# COMPUTE_CLUSTER0_DRU register map
Vendor: Texas Instruments
Peripheral module from a debugger description file (folder am65x).
Registers are 64-bit, read-only, reset 0x0 unless marked. A register's access mark holds for its fields unless they carry their own. Offsets are as the file gives them; lines under a group give offsets from that group; [hi:lo] are bit positions; {n}, {i} and the like mark numbered series; 'fields as' and 'values as' point back to an identical list; <NAME> marks a mode.

## COMPUTE_CLUSTER0_DRU
0x00 DRU_PID reset 0x662C0900 — Peripheral ID Register
  [31:0] REVISION
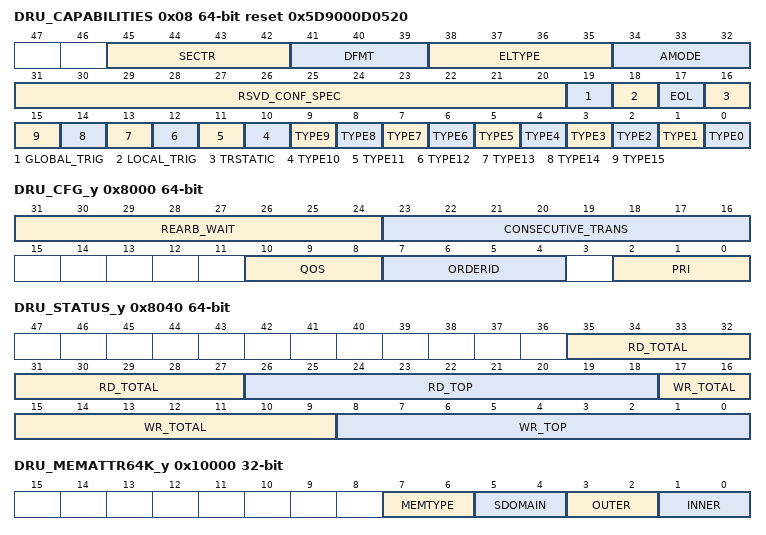
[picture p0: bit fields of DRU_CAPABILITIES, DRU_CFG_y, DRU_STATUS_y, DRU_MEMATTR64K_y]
0x08 DRU_CAPABILITIES reset 0x5D9000D0520 — DRU Capabilities: Lists the capabilities of the channel for TR TYPE and formatting functions
  [45:42] SECTR, [41:39] DFMT, [38:35] ELTYPE, [34:32] AMODE, [31:20] RSVD_CONF_SPEC, [19] GLOBAL_TRIG, [18] LOCAL_TRIG, [17] EOL, [16] TRSTATIC, [n] TYPE{n} (n=0..15)
0x4000 DRU_SHARED_EVT_SET access per field — DRU Shared Event Set Register
  [0] PROT_ERR wo
0x4040 DRU_COMP_EVT_SET0 wo — DRU Completion Event Set Register
  [n] COMP_EVT{n} (n=0..63)
0x4080 DRU_ERR_EVT_SET0 wo — DRU Error Event Set Register
  [n] ERR_EVT{n} (n=0..63)
0x40C0 DRU_LOCAL_EVT_SET0 wo — DRU Local Event Set Register
  [n] COMP_EVT{n} (n=0..63)
0x8000 DRU_CFG_y access per field — Configuration Register for Queue 'y' Offset = 8000h + (y * 8h); where y = 0h to 4h
  [31:24] REARB_WAIT rw, [23:16] CONSECUTIVE_TRANS rw, [10:8] QOS rw, [7:4] ORDERID rw, [2:0] PRI rw
0x8040 DRU_STATUS_y — Status Register for Queue 'y' Offset = 8040h + (y * 8h); where y = 0h to 4h
  [35:27] RD_TOTAL, [26:18] RD_TOP, [17:9] WR_TOTAL, [8:0] WR_TOP
0x10000 DRU_MEMATTR64K_y 32-bit rw — The Memory Attribute register contains the attributes for all the 64K mapped regions. Offset = 10000h + (y * 4h); where y = 0h to 7Fh
  [7:6] MEMTYPE — Defines the type of the memory
  [5:4] SDOMAIN — Defines the shareability domain of the memory
  [3:2] OUTER — Defines the outer allocatability of the memory
  [1:0] INNER — Defines the inner allocatability of the memory
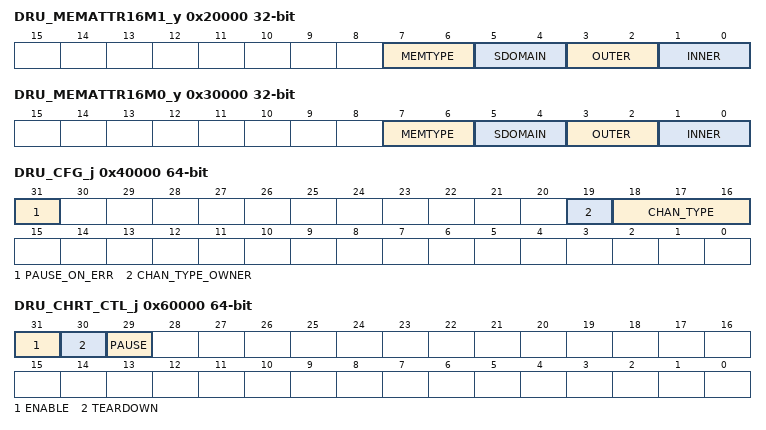
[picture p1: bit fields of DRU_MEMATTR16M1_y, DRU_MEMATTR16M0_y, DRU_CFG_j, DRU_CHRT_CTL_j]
0x20000 DRU_MEMATTR16M1_y 32-bit rw — The Memory Attribute register contains the attributes for all the second 16M mapped regions. Offset = 20000h + (y * 4h); where y = 0h to 7FFh
  fields as DRU_MEMATTR64K_y
0x30000 DRU_MEMATTR16M0_y 32-bit rw — The Memory Attribute register contains the attributes for all the first 16M mapped regions. Offset = 30000h + (y * 4h); where y = 0h to 7Fh
  fields as DRU_MEMATTR64K_y
0x40000 DRU_CFG_j access per field — Channel Configuration Register. The Channel Configuration Register is used to initialize static mode settings for the DMA Channel. The register may only be written when the chanel is disable in the ch_enable field in the REALTIME CONTROL register is 0. Offset = 40000h + (j * 100h); where j = 0h to 3Fh
  [31] PAUSE_ON_ERR rw, [19] CHAN_TYPE_OWNER rw, [18:16] CHAN_TYPE ro
0x40020 DRU_CHOES0_j access per field — The Output Event Steering Registers are used to specify a global event number to generate anytime the required event generation criteria specified in a TR are met. A single event with the event number set equal to the value in the corresponding register will be generated. This register is provided in order to allow security SW to lock down which events in the global space any given channel/ thread is allowed to generate Offset = 40020h + (j * 100h); where j = 0h to 3Fh
  [15:0] EVT_NUM rw
0x40060 DRU_CHST_SCHED_j rw — Channel Static Scheduler Config Register Offset = 40060h + (j * 100h); where j = 0h to 3Fh
  [2:0] QUEUE
0x60000 DRU_CHRT_CTL_j access per field — The channel realtime control register contains real-time cotrol and status information for the DMA Channel. The fields in this regsiter can be changed while the channel is in operation. Offset = 60000h + (j * 100h); where j = 0h to 3Fh
  [31] ENABLE rw, [30] TEARDOWN rw, [29] PAUSE rw
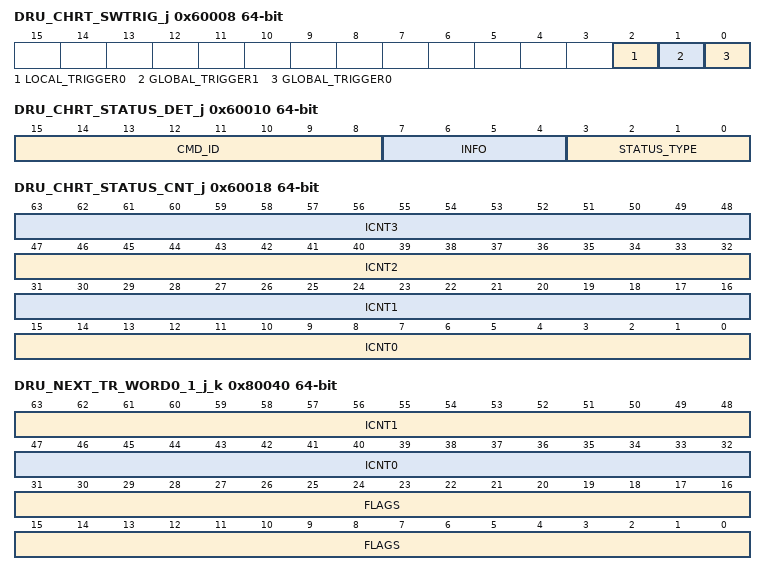
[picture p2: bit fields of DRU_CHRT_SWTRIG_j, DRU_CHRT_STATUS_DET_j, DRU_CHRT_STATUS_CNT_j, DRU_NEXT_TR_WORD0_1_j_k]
0x60008 DRU_CHRT_SWTRIG_j access per field — The Software Trigger Register provides a mechanism by which software can directly trigger the channel in a secure way. Offset = 60008h + (j * 100h); where j = 0h to 3Fh
  [2] LOCAL_TRIGGER0 rw, [1] GLOBAL_TRIGGER1 rw, [0] GLOBAL_TRIGGER0 rw
0x60010 DRU_CHRT_STATUS_DET_j — The channel status details Offset = 60010h + (j * 100h); where j = 0h to 3Fh
  [15:8] CMD_ID, [7:4] INFO, [3:0] STATUS_TYPE
0x60018 DRU_CHRT_STATUS_CNT_j — The channel count details Offset = 60018h + (j * 100h); where j = 0h to 3Fh
  [16n+15:16n] ICNT{n} (n=0..3)
0x80040 DRU_NEXT_TR_WORD0_1_j_k — The first TR submission word Offset = 80040h + (j * 100h) + (k * 40h); where j = 0h to 3Fh, k = 0h to 2h
  [63:48] ICNT1, [47:32] ICNT0, [31:0] FLAGS
0x80048 DRU_NEXT_TR_WORD2_3_j_k — The second TR submission word Offset = 80048h + (j * 100h) + (k * 40h); where j = 0h to 3Fh, k = 0h to 2h
  [47:0] SRC_ADDR
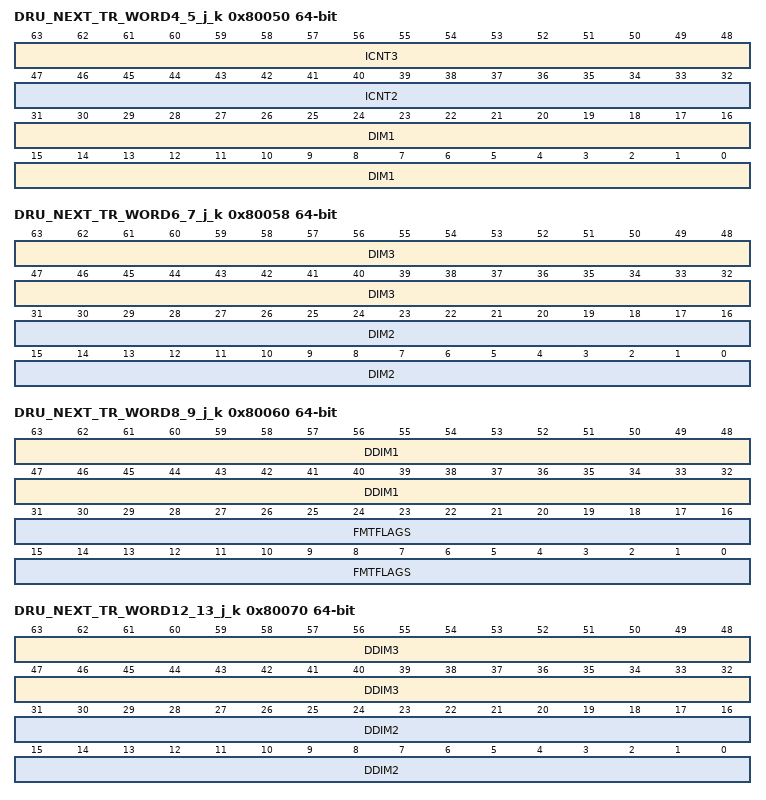
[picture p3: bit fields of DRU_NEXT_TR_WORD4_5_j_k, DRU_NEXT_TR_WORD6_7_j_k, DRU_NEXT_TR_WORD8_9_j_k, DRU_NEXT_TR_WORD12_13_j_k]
0x80050 DRU_NEXT_TR_WORD4_5_j_k — The third TR submission word Offset = 80050h + (j * 100h) + (k * 40h); where j = 0h to 3Fh, k = 0h to 2h
  [63:48] ICNT3, [47:32] ICNT2, [31:0] DIM1
0x80058 DRU_NEXT_TR_WORD6_7_j_k — The fourth TR submission word Offset = 80058h + (j * 100h) + (k * 40h); where j = 0h to 3Fh, k = 0h to 2h
  [63:32] DIM3, [31:0] DIM2
0x80060 DRU_NEXT_TR_WORD8_9_j_k — The fifth TR submission word Offset = 80060h + (j * 100h) + (k * 40h); where j = 0h to 3Fh, k = 0h to 2h
  [63:32] DDIM1, [31:0] FMTFLAGS
0x80068 DRU_NEXT_TR_WORD10_11_j_k — The sixth TR submission word Offset = 80068h + (j * 100h) + (k * 40h); where j = 0h to 3Fh, k = 0h to 2h
  [47:0] DADDR
0x80070 DRU_NEXT_TR_WORD12_13_j_k — The seventh TR submission word Offset = 80070h + (j * 100h) + (k * 40h); where j = 0h to 3Fh, k = 0h to 2h
  [63:32] DDIM3, [31:0] DDIM2
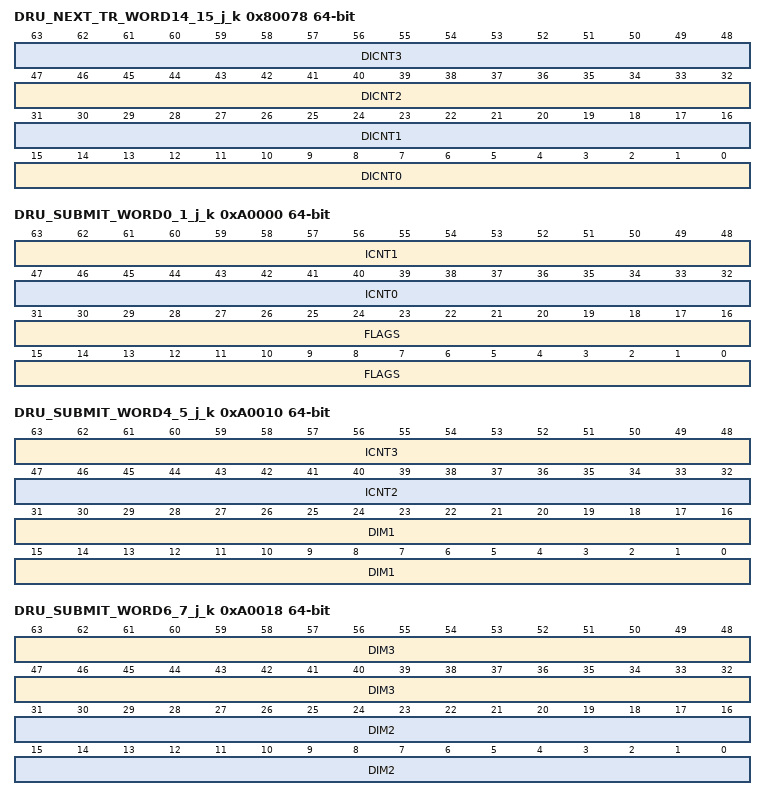
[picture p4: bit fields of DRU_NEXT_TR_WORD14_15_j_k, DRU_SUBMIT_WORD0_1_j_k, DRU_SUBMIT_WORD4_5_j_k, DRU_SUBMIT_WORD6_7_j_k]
0x80078 DRU_NEXT_TR_WORD14_15_j_k — The eight TR submission word Offset = 80078h + (j * 100h) + (k * 40h); where j = 0h to 3Fh, k = 0h to 2h
  [16n+15:16n] DICNT{n} (n=0..3)
0xA0000 DRU_SUBMIT_WORD0_1_j_k rw — The first TR submission word Offset = A0000h + (j * 100h) + (k * 40h); where j = 0h to 3Fh, k = 0h to 2h
  [63:48] ICNT1, [47:32] ICNT0, [31:0] FLAGS
0xA0008 DRU_SUBMIT_WORD2_3_j_k access per field — The second TR submission word Offset = A0008h + (j * 100h) + (k * 40h); where j = 0h to 3Fh, k = 0h to 2h
  [47:0] SRC_ADDR rw
0xA0010 DRU_SUBMIT_WORD4_5_j_k rw — The third TR submission word Offset = A0010h + (j * 100h) + (k * 40h); where j = 0h to 3Fh, k = 0h to 2h
  [63:48] ICNT3, [47:32] ICNT2, [31:0] DIM1
0xA0018 DRU_SUBMIT_WORD6_7_j_k rw — The fourth TR submission word Offset = A0018h + (j * 100h) + (k * 40h); where j = 0h to 3Fh, k = 0h to 2h
  [63:32] DIM3, [31:0] DIM2
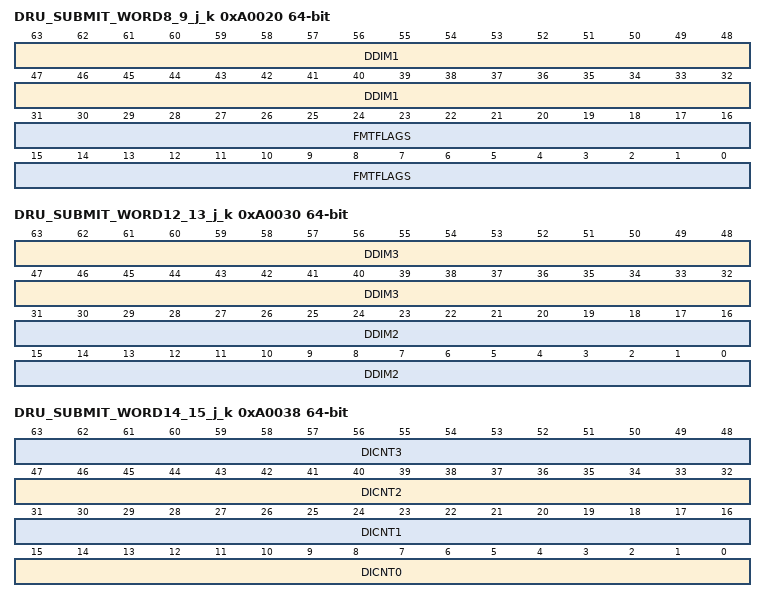
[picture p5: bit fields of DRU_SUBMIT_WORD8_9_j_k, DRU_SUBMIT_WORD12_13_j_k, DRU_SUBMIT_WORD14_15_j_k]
0xA0020 DRU_SUBMIT_WORD8_9_j_k rw — The fifth TR submission word Offset = A0020h + (j * 100h) + (k * 40h); where j = 0h to 3Fh, k = 0h to 2h
  [63:32] DDIM1, [31:0] FMTFLAGS
0xA0028 DRU_SUBMIT_WORD10_11_j_k access per field — The sixth TR submission word Offset = A0028h + (j * 100h) + (k * 40h); where j = 0h to 3Fh, k = 0h to 2h
  [47:0] DADDR rw
0xA0030 DRU_SUBMIT_WORD12_13_j_k rw — The seventh TR submission word Offset = A0030h + (j * 100h) + (k * 40h); where j = 0h to 3Fh, k = 0h to 2h
  [63:32] DDIM3, [31:0] DDIM2
0xA0038 DRU_SUBMIT_WORD14_15_j_k rw — The eight TR submission word Offset = A0038h + (j * 100h) + (k * 40h); where j = 0h to 3Fh, k = 0h to 2h
  [16n+15:16n] DICNT{n} (n=0..3)
0xE0000 DRU_CAUSE_y — Offset = E0000h + (y * 8h); where y = 0h to 3h
  [4n+3] R_ERR{n} (n=1..15) — Masked error bit for Tx channel n+{n}
  [4n+2] R_PEND{n} (n=1..15) — Masked completion ring pending bit for Rx channel n+{n}
  [4n+1] T_ERR{n} (n=1..15) — Masked error bit for Tx channel n+{n}
  [4n] T_PEND{n} (n=1..15) — Masked completion ring pending bit for Tx channel n+{n}
  [3] R_ERR0 — Masked error bit for Tx channel n
  [2] R_PEND0 — Masked completion ring pending bit for Rx channel n
  [1] T_ERR0 — Masked error bit for Tx channel n
  [0] T_PEND0 — Masked completion ring pending bit for Tx channel n
